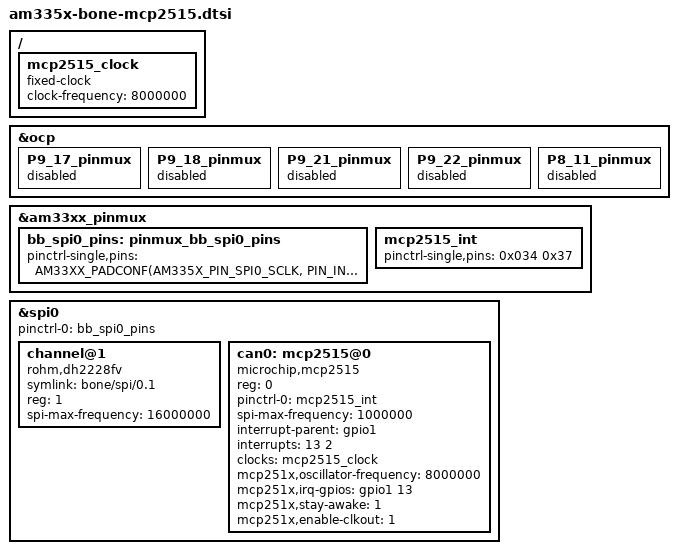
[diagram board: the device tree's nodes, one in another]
// SPDX-License-Identifier: GPL-2.0-only
/*
 * Copyright (C) 2013 CircuitCo
 * Configuration for SPI0 on connector pins P9.22 P9.21 P9.18 P9.17
 */

&ocp {
	P9_17_pinmux { status = "disabled"; };	/* P9_17 spi0_cs0.spi0_cs0 		=> CS 	*/
	P9_18_pinmux { status = "disabled"; };	/* P9_18 spi0_d1.spi0_d1 		=> MOSI */
	P9_21_pinmux { status = "disabled"; };	/* P9_21 spi0_d0.spi0_d0 		=> MISO */
	P9_22_pinmux { status = "disabled"; };	/* P9_22 spi0_sclk.spi0_sclk 	=> SCK 	*/
    P8_11_pinmux { status = "disabled"; };  /* irq 							=> INT 	*/
};

&am33xx_pinmux {
	bb_spi0_pins: pinmux_bb_spi0_pins {
		pinctrl-single,pins = <
			AM33XX_PADCONF(AM335X_PIN_SPI0_SCLK, PIN_INPUT, MUX_MODE0)	/* P9_22 (A17) spi0_sclk.spi0_sclk 	*/
			AM33XX_PADCONF(AM335X_PIN_SPI0_D0, PIN_INPUT, MUX_MODE0)	/* P9_21 (B17) spi0_d0.spi0_d0 		*/
			AM33XX_PADCONF(AM335X_PIN_SPI0_D1, PIN_INPUT, MUX_MODE0)	/* P9_18 (B16) spi0_d1.spi0_d1 		*/
			AM33XX_PADCONF(AM335X_PIN_SPI0_CS0, PIN_INPUT, MUX_MODE0)	/* P9_17 (A16) spi0_cs0.spi0_cs0 	*/
		>;
	};

    mcp2515_int: mcp2515_int {
        pinctrl-single,pins = < 0x034 0x37 >;
    };
};

/ {
    mcp2515_clock: mcp2515_clock {
        compatible = "fixed-clock";
        #clock-cells = <0>;
        clock-frequency = <8000000>;
    };
};

&spi0 {
	#address-cells = <1>;
	#size-cells = <0>;

	status = "okay";
	pinctrl-names = "default";
	pinctrl-0 = <&bb_spi0_pins>;

	/*
	 * Select the D0 pin as output and D1 as
	 * input. The default is D0 as input and
	 * D1 as output.
	 */
	//ti,pindir-d0-out-d1-in;

	// channel@0 {
	// 	#address-cells = <1>;
	// 	#size-cells = <0>;

	// 	compatible = "rohm,dh2228fv";
	// 	symlink = "bone/spi/0.0";

	// 	reg = <0>;
	// 	spi-max-frequency = <16000000>;
	// 	spi-cpha;
	// };

	channel@1 {
		#address-cells = <1>;
		#size-cells = <0>;

		compatible = "rohm,dh2228fv";
		symlink = "bone/spi/0.1";

		reg = <1>;
		spi-max-frequency = <16000000>;
	};

    can0: mcp2515@0 {
        status = "okay";
        reg = <0>;
        compatible = "microchip,mcp2515";
        pinctrl-names = "default";
        pinctrl-0 = <&mcp2515_int>;
        spi-max-frequency = <1000000>;
        interrupt-parent = <&gpio1>;
        interrupts = <13 2>;
        clocks = <&mcp2515_clock>;

        mcp251x,oscillator-frequency = <8000000>;
        mcp251x,irq-gpios = <&gpio1 13 0>;
        mcp251x,stay-awake = <1>;
        mcp251x,enable-clkout = <1>;
    };
};
